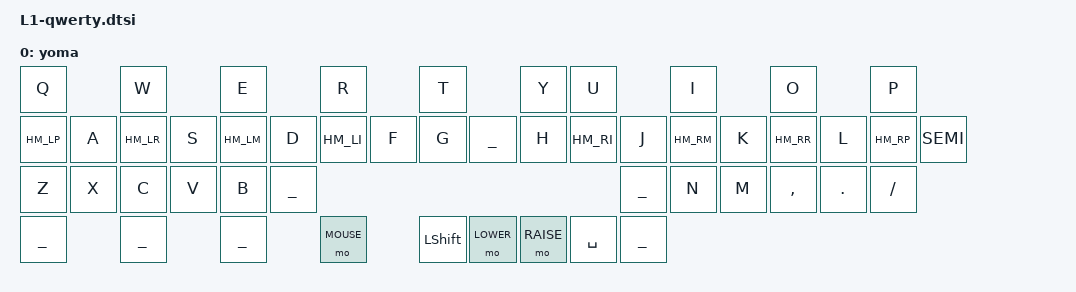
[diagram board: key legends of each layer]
/**
 *
 */

/ {
  keymap {
    compatible = "zmk,keymap";

	default_layer {
		label = "yoma";
		bindings = <
	&kp Q           &kp W           &kp E           &kp R           &kp T                                               &kp Y           &kp U           &kp I           &kp O           &kp P
	HM_LP A         HM_LR S         HM_LM D         HM_LI F         &kp G                               ________        &kp H           HM_RI J         HM_RM K         HM_RR L         HM_RP SEMI
	&kp Z           &kp X           &kp C           &kp V           &kp B           ________            ________        &kp N           &kp M           &kp COMMA       &kp DOT         &kp FSLH
	________        ________        ________        &mo MOUSE       &kp LSHFT       &mo LOWER           &mo RAISE       &kp SPACE       ________
		>;
		// Wheel: clockwise turns the volume up
		sensor-bindings = <&inc_dec_kp C_VOL_UP C_VOL_DN>;
	};
  };
};
